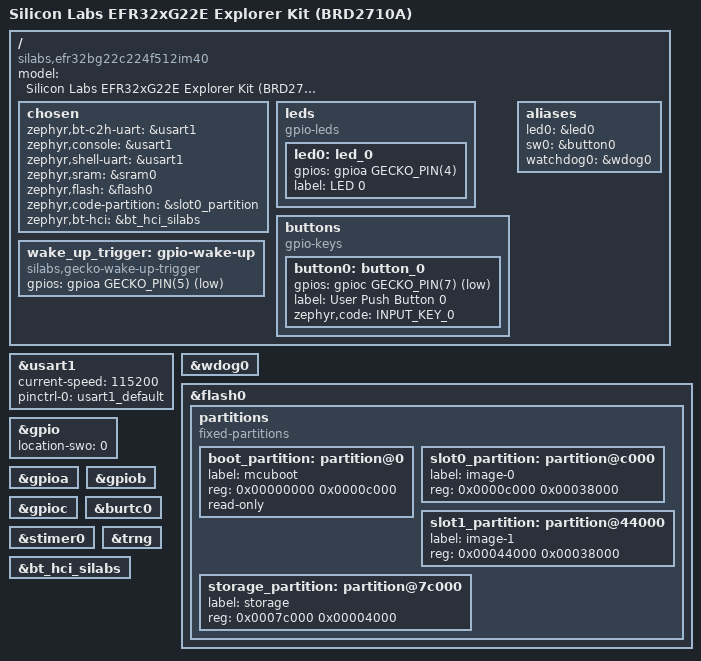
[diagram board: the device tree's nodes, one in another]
/*
 * Copyright (c) 2025 blerpc project
 *
 * SPDX-License-Identifier: Apache-2.0
 */

/dts-v1/;
#include <silabs/efr32bg22.dtsi>
#include <silabs/efr32bg2x-pinctrl.dtsi>
#include <zephyr/dt-bindings/input/input-event-codes.h>
#include <silabs/gpio_gecko.h>

/ {
	model = "Silicon Labs EFR32xG22E Explorer Kit (BRD2710A)";
	compatible = "silabs,efr32bg22c224f512im40", "silabs,xg22_ek2710a",
		"silabs,efr32bg22";

	chosen {
		zephyr,bt-c2h-uart = &usart1;
		zephyr,console = &usart1;
		zephyr,shell-uart = &usart1;
		zephyr,sram = &sram0;
		zephyr,flash = &flash0;
		zephyr,code-partition = &slot0_partition;
		zephyr,bt-hci = &bt_hci_silabs;
	};

	leds {
		compatible = "gpio-leds";
		led0: led_0 {
			gpios = <&gpioa GECKO_PIN(4) GPIO_ACTIVE_HIGH>;
			label = "LED 0";
		};
	};

	buttons {
		compatible = "gpio-keys";
		button0: button_0 {
			gpios = <&gpioc GECKO_PIN(7) GPIO_ACTIVE_LOW>;
			label = "User Push Button 0";
			zephyr,code = <INPUT_KEY_0>;
		};
	};

	wake_up_trigger: gpio-wake-up {
		compatible = "silabs,gecko-wake-up-trigger";
		gpios = <&gpioa GECKO_PIN(5) GPIO_ACTIVE_LOW>;
	};

	aliases {
		led0 = &led0;
		sw0 = &button0;
		watchdog0 = &wdog0;
	};
};

&usart1 {
	current-speed = <115200>;
	status = "okay";
	pinctrl-0 = <&usart1_default>;
	pinctrl-names = "default";
};

&wdog0 {
	status = "okay";
};

&flash0 {
	partitions {
		compatible = "fixed-partitions";
		#address-cells = <1>;
		#size-cells = <1>;

		/* Reserve 48 KiB for the bootloader */
		boot_partition: partition@0 {
			label = "mcuboot";
			reg = <0x00000000 0x0000c000>;
			read-only;
		};

		/* Reserve 224 KiB for the application in slot 0 */
		slot0_partition: partition@c000 {
			label = "image-0";
			reg = <0x0000c000 0x00038000>;
		};

		/* Reserve 224 KiB for the application in slot 1 */
		slot1_partition: partition@44000 {
			label = "image-1";
			reg = <0x00044000 0x00038000>;
		};

		/* Set 16 KiB of storage at the end of the 512 KiB of flash */
		storage_partition: partition@7c000 {
			label = "storage";
			reg = <0x0007c000 0x00004000>;
		};
	};
};

&gpio {
	location-swo = <0>;
	status = "okay";
};

&gpioa {
	status = "okay";
};

&gpiob {
	status = "okay";
};

&gpioc {
	status = "okay";
};

&burtc0 {
	status = "okay";
};

&stimer0 {
	status = "okay";
};

&trng {
	status = "okay";
};

&bt_hci_silabs {
	status = "okay";
};
